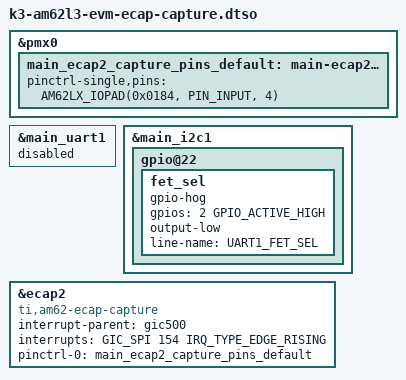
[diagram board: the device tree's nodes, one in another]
// SPDX-License-Identifier: GPL-2.0
/*
 * DT Overlay for enabling ECAP in capture mode on AM62L3-EVM
 *
 * Copyright (C) 2023 Texas Instruments Incorporated - https://www.ti.com/
 */

/dts-v1/;
/plugin/;

#include <dt-bindings/gpio/gpio.h>
#include <dt-bindings/interrupt-controller/arm-gic.h>
#include "k3-pinctrl.h"

&pmx0 {
	main_ecap2_capture_pins_default: main-ecap2-capture-pins-default {
		pinctrl-single,pins = <
			AM62LX_IOPAD(0x0184, PIN_INPUT, 4) /* (B10) MCASP0_AXR2.ECAP2_IN_APWM_OUT */
		>;
	};
};

&main_uart1 {
	status = "disabled";
};

&main_i2c1 {
	gpio@22 {
		fet_sel {
			/* P02 - UART1_FET_SEL */
			gpio-hog;
			gpios = <2 GPIO_ACTIVE_HIGH>;
			output-low;
			line-name = "UART1_FET_SEL";
		};
	};
};

&ecap2 {
	/* ECAP in capture mode */
	/* P2 of J6 */
	compatible = "ti,am62-ecap-capture";
	interrupt-parent = <&gic500>;
	interrupts = <GIC_SPI 154 IRQ_TYPE_EDGE_RISING>;
	pinctrl-names = "default";
	pinctrl-0 = <&main_ecap2_capture_pins_default>;
	status = "okay";
};
